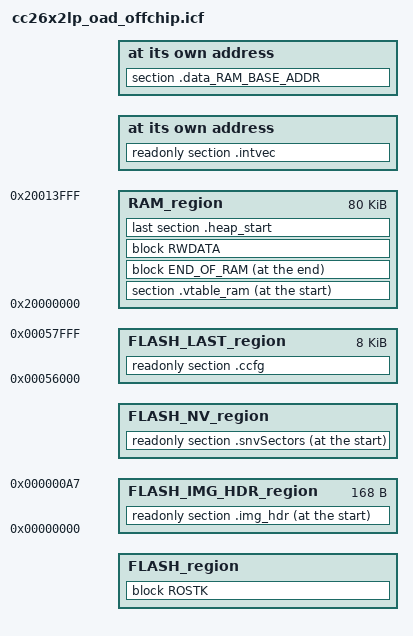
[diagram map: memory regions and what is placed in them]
/******************************************************************************

 @file  cc26x2lp_oad_offchip.icf

 @brief IAR Linker configuration file for MAC-Sensor on CC13x2 LaunchPad

 Group: WCS LPC
 Target Device: cc13xx_cc26xx

 ******************************************************************************
 
 Copyright (c) 2018-2023, Texas Instruments Incorporated
 All rights reserved.

 Redistribution and use in source and binary forms, with or without
 modification, are permitted provided that the following conditions
 are met:

 *  Redistributions of source code must retain the above copyright
    notice, this list of conditions and the following disclaimer.

 *  Redistributions in binary form must reproduce the above copyright
    notice, this list of conditions and the following disclaimer in the
    documentation and/or other materials provided with the distribution.

 *  Neither the name of Texas Instruments Incorporated nor the names of
    its contributors may be used to endorse or promote products derived
    from this software without specific prior written permission.

 THIS SOFTWARE IS PROVIDED BY THE COPYRIGHT HOLDERS AND CONTRIBUTORS "AS IS"
 AND ANY EXPRESS OR IMPLIED WARRANTIES, INCLUDING, BUT NOT LIMITED TO,
 THE IMPLIED WARRANTIES OF MERCHANTABILITY AND FITNESS FOR A PARTICULAR
 PURPOSE ARE DISCLAIMED. IN NO EVENT SHALL THE COPYRIGHT OWNER OR
 CONTRIBUTORS BE LIABLE FOR ANY DIRECT, INDIRECT, INCIDENTAL, SPECIAL,
 EXEMPLARY, OR CONSEQUENTIAL DAMAGES (INCLUDING, BUT NOT LIMITED TO,
 PROCUREMENT OF SUBSTITUTE GOODS OR SERVICES; LOSS OF USE, DATA, OR PROFITS;
 OR BUSINESS INTERRUPTION) HOWEVER CAUSED AND ON ANY THEORY OF LIABILITY,
 WHETHER IN CONTRACT, STRICT LIABILITY, OR TORT (INCLUDING NEGLIGENCE OR
 OTHERWISE) ARISING IN ANY WAY OUT OF THE USE OF THIS SOFTWARE,
 EVEN IF ADVISED OF THE POSSIBILITY OF SUCH DAMAGE.

 ******************************************************************************
 
 
 *****************************************************************************/

/* Intvec start */
define symbol FLASH_BASE = 0x00000000;
define symbol WORD_SIZE           = 4;
define symbol FLASH_MEM_ALIGN     = WORD_SIZE;

if (!isdefinedsymbol(NVOCMP_NVPAGES)) {
  define symbol NVOCMP_NVPAGES  = 2;
}

/* Memory Regions */
define symbol FLASH_NV_BASE = (0x56000 - (NVOCMP_NVPAGES * 0x2000)); // NV Flash base
define symbol FLASH_NV_SIZE = (NVOCMP_NVPAGES * 0x2000);

define symbol FLASH_LAST_BASE     = 0x00056000;
define symbol FLASH_LAST_SIZE    = 0x00002000;

define symbol RAM_BASE           = 0x20000000;
define symbol RAM_SIZE           = 0x14000;

define symbol OAD_HDR_START           = FLASH_BASE;
define symbol OAD_HDR_SIZE            = 0xA8;
define symbol OAD_HDR_END             = (OAD_HDR_START + OAD_HDR_SIZE -1);
define symbol FLASH_START             = OAD_HDR_END + 1;
define symbol FLASH_SIZE              = (FLASH_NV_BASE - FLASH_START);
define symbol PAGE_SIZE               = 0x2000;

/* Define a memory region that covers the entire 4 GB addressable space */
define memory mem with size = 4G;

/* Define a region for the on-chip flash */
define region FLASH_region = mem:[from FLASH_START size FLASH_SIZE];

/* OAD Image Header */
define region FLASH_IMG_HDR_region = mem:[from OAD_HDR_START size OAD_HDR_SIZE];

/* Define a region for the on-chip flash used for NV storage */
define region FLASH_NV_region = mem:[from FLASH_NV_BASE size FLASH_NV_SIZE];

/* Define a region for the last flash page */
define region FLASH_LAST_region = mem:[from FLASH_LAST_BASE size FLASH_LAST_SIZE];

/* Internal RAM for data used by application */
define region RAM_region = mem:[from RAM_BASE size RAM_SIZE];

/* Place the interrupt vectors at the start of flash */
place at address mem:FLASH_START { readonly section .intvec };
keep { section .intvec};

/* Place the CCA area at the end of flash */
"AGAMA_CCFG_AREA":
place noload in FLASH_LAST_region { readonly section .ccfg };

//place in FLASH_region { readonly section .const object mac_user_config.o };

// Flash OAD Image Header
place at start of FLASH_IMG_HDR_region { readonly section .img_hdr };
keep                            { readonly section .img_hdr };

/*
place in FLASH_region { section .resetVecs };



place in FLASH_region { 
	section .const,
	section .constdata,
	section .rodata,
	section .cinit,
	section .pinit,
	section .init_array,
	section .emb_text
};
*/

/* Place remaining 'read only' in Flash */
//place in FLASH_region { readonly };

/* Mark the beginning of the NV Flash page */
place at start of FLASH_NV_region { readonly section .snvSectors };

define block ROSTK with alignment=WORD_SIZE{ ro };
// All other pieces of codes:
place in FLASH_region {block ROSTK };

/* Place .vtable_ram in start of RAM */

place at start of RAM_region { section .vtable_ram };
/*
place in RAM_region  { 
	section .data,
	section .bss,
	section .vtable,
	section .vtable_ram,
	section .vtable_ram,
	section .sysmem,
	section .nonretenvar,
};

*/

/*
 * Define CSTACK block to contain .stack section. This enables the IAR IDE
 * to properly show the stack content during debug. Place stack at end of
 * retention RAM, do not initialize (initializing the stack will destroy the
 * return address from the initialization code, causing the processor to branch
 * to zero and fault)
 */
define symbol STACKSIZE = 1024;
define block CSTACK with alignment = 8, size = STACKSIZE { section .stack };

//place at end of RAM_region { block CSTACK };
if (isdefinedsymbol(ROM_TIMACDataAddr)) {
    place at address mem:ROM_TIMACDataAddr {section .data_RAM_BASE_ADDR };
}

/* Export stack top symbol. Used by startup file */
define exported symbol STACK_TOP = end(RAM_region) + 1;

define block RWDATA { rw };

define section .heap_start            { public heapStart: };
define section .heap_end              { public heapEnd: };
define block   HEAP_END with size = 1 { section .heap_end };

define block END_OF_RAM with fixed order {
                                        block HEAP_END,
                                        block CSTACK
                                      };
place at end of RAM_region { block END_OF_RAM };

place in RAM_region { block RWDATA,
               last section .heap_start};



initialize by copy { readwrite };
do not initialize { section .stack, section .noinit};

/*
 * The USE_TIRTOS_ROM symbol is defined internally in the build flow (using
 * --config_def USE_TIRTOS_ROM=1) for TI-RTOS applications whose app.cfg file
 * specifies to use the ROM.
 */
if (isdefinedsymbol(USE_TIRTOS_ROM)) {
    include "TIRTOS_ROM.icf";
}
